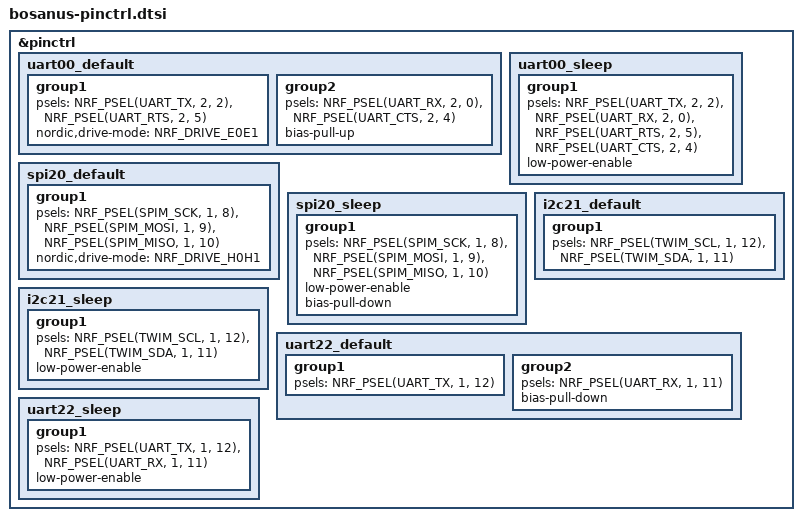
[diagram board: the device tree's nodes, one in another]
/*
 * Copyright (c) 2026 Embeint Inc
 * SPDX-License-Identifier: Apache-2.0
 */

&pinctrl {
	uart00_default: uart00_default {
		group1 {
			psels = <NRF_PSEL(UART_TX, 2, 2)>,
				<NRF_PSEL(UART_RTS, 2, 5)>;
			nordic,drive-mode = <NRF_DRIVE_E0E1>;
		};

		group2 {
			psels = <NRF_PSEL(UART_RX, 2, 0)>,
				<NRF_PSEL(UART_CTS, 2, 4)>;
			bias-pull-up;
		};
	};

	uart00_sleep: uart00_sleep {
		group1 {
			psels = <NRF_PSEL(UART_TX, 2, 2)>,
				<NRF_PSEL(UART_RX, 2, 0)>,
				<NRF_PSEL(UART_RTS, 2, 5)>,
				<NRF_PSEL(UART_CTS, 2, 4)>;
			low-power-enable;
		};
	};

	spi20_default: spi20_default {
		group1 {
			psels = <NRF_PSEL(SPIM_SCK, 1, 8)>,
				<NRF_PSEL(SPIM_MOSI, 1, 9)>,
				<NRF_PSEL(SPIM_MISO, 1, 10)>;
			nordic,drive-mode = <NRF_DRIVE_H0H1>;
		};
	};

	spi20_sleep: spi20_sleep {
		group1 {
			psels = <NRF_PSEL(SPIM_SCK, 1, 8)>,
				<NRF_PSEL(SPIM_MOSI, 1, 9)>,
				<NRF_PSEL(SPIM_MISO, 1, 10)>;
			low-power-enable;
			bias-pull-down;
		};
	};

	i2c21_default: i2c21_default {
		group1 {
			psels = <NRF_PSEL(TWIM_SCL, 1, 12)>,
				<NRF_PSEL(TWIM_SDA, 1, 11)>;
		};
	};

	i2c21_sleep: i2c21_sleep {
		group1 {
			psels = <NRF_PSEL(TWIM_SCL, 1, 12)>,
				<NRF_PSEL(TWIM_SDA, 1, 11)>;
				low-power-enable;
		};
	};

	uart22_default: uart22_default {
		group1 {
			psels = <NRF_PSEL(UART_TX, 1, 12)>;
		};

		group2 {
			psels = <NRF_PSEL(UART_RX, 1, 11)>;
			bias-pull-down;
		};
	};

	uart22_sleep: uart22_sleep {
		group1 {
			psels = <NRF_PSEL(UART_TX, 1, 12)>,
				<NRF_PSEL(UART_RX, 1, 11)>;
			low-power-enable;
		};
	};
};
